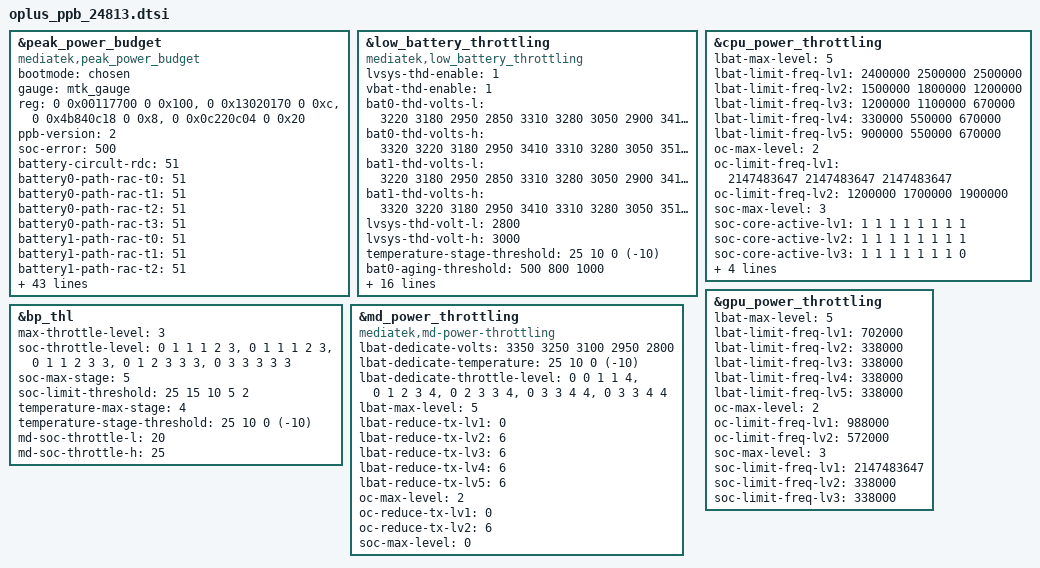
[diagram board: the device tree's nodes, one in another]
// SPDX-License-Identifier: GPL-2.0-only
/*
* Copyright (C) 2021-2020 Oplus. All rights reserved.
*/
#include <dt-bindings/iio/mt635x-auxadc.h>
#include <dt-bindings/pinctrl/mt6991-pinfunc.h>
#include <dt-bindings/pinctrl/mt65xx.h>

&peak_power_budget {
	compatible = "mediatek,peak_power_budget";
	bootmode = <&chosen>;
	gauge = <&mtk_gauge>;
	reg = <0 0x00117700 0 0x100>,
		<0 0x13020170 0 0xc>,
		<0 0x4b840c18 0 0x8>,
		<0 0x0c220c04 0 0x20>;
	reg-names = "ppb_sram",
		"hpt_ctrl","gpu_dbg", "cpu_dbg";

	ppb-version = <2>;
	soc-error = <500>;
	battery-circult-rdc  = <51>;
	battery0-path-rac-t0 = <51>;
	battery0-path-rac-t1 = <51>;
	battery0-path-rac-t2 = <51>;
	battery0-path-rac-t3 = <51>;
	battery1-path-rac-t0 = <51>;
	battery1-path-rac-t1 = <51>;
	battery1-path-rac-t2 = <51>;
	battery1-path-rac-t3 = <51>;
	battery2-path-rac-t0 = <51>;
	battery2-path-rac-t1 = <51>;
	battery2-path-rac-t2 = <51>;
	battery2-path-rac-t3 = <51>;
	temperature-threshold = <25 10 0>;
	system-ocp = <15000>;
	system-uvlo = <2400>;

	soc-max-level = <3>;     //+lv3
	soc-hpt-ctrl-lv1 = <7>;  //lv1 pre-uv on
	soc-hpt-ctrl-lv2 = <0>;  //lv2 pre-uv off
	soc-hpt-ctrl-lv3 = <0>;  //lv3 pre-uv off

	bat-ocv-table-num = <6>;
	bat0-ocv-table-t0-temperature = <50>;
		bat0-ocv-table-t0-qmax = <6498>;
	bat0-ocv-table-t0-size = <100>;
	bat0-ocv-table-t0 = <
		0	44457 	0 	271
656	44330 	101 	271
1313	44219 	202 	268
1969	44119 	303 	270
2625	44024 	404 	272
3282	43926 	505 	267
3938	43829 	606 	270
4594	43730 	707 	268
5251	43630 	808 	269
5907	43527 	909 	272
6563	43422 	1010 	273
7220	43313 	1111 	267
7876	43209 	1212 	280
8532	43097 	1313 	285
9189	42982 	1414 	286
9845	42864 	1515 	286
10501	42745 	1616 	285
11157	42625 	1717 	283
11814	42506 	1818 	288
12470	42385 	1919 	292
13126	42264 	2020 	296
13783	42142 	2121 	303
14439	42023 	2222 	309
15095	41901 	2323 	319
15752	41782 	2424 	328
16408	41661 	2525 	339
17064	41537 	2626 	352
17721	41409 	2727 	364
18377	41267 	2828 	378
19033	41073 	2929 	340
19690	40883 	3030 	304
20346	40719 	3131 	284
21002	40587 	3232 	278
21659	40470 	3333 	274
22315	40358 	3434 	272
22971	40253 	3535 	271
23628	40149 	3636 	271
24284	40047 	3737 	272
24940	39951 	3838 	276
25597	39855 	3939 	282
26253	39763 	4040 	282
26909	39671 	4141 	287
27566	39582 	4242 	291
28222	39496 	4343 	296
28878	39410 	4444 	306
29534	39326 	4545 	315
30191	39236 	4646 	324
30847	39121 	4747 	313
31503	38982 	4848 	290
32160	38836 	4950 	279
32816	38725 	5050 	286
33472	38611 	5151 	286
34129	38500 	5253 	286
34785	38394 	5354 	286
35441	38293 	5454 	288
36098	38191 	5556 	298
36754	38072 	5657 	305
37410	37953 	5758 	313
38067	37837 	5859 	320
38723	37722 	5960 	328
39379	37607 	6061 	335
40036	37511 	6162 	316
40692	37441 	6263 	311
41348	37377 	6364 	313
42005	37310 	6465 	327
42661	37231 	6566 	364
43317	37122 	6667 	452
43974	37010 	6768 	300
44630	36897 	6869 	275
45286	36777 	6970 	250
45943	36651 	7071 	225
46599	36521 	7172 	200
47255	36387 	7273 	175
47912	36241 	7374 	150
48568	36089 	7475 	125
49224	35931 	7576 	100
49880	35769 	7677 	100
50537	35609 	7778 	100
51193	35452 	7879 	100
51849	35300 	7980 	100
52506	35151 	8081 	100
53162	34999 	8182 	100
53818	34844 	8283 	100
54475	34687 	8384 	100
55131	34516 	8485 	100
55787	34337 	8586 	100
56444	34146 	8687 	100
57100	33943 	8788 	100
57756	33727 	8889 	350
58413	33491 	8990 	600
59069	33249 	9091 	600
59725	33009 	9192 	600
60382	32772 	9293 	548
61038	32537 	9394 	495
61694	32294 	9495 	443
62351	32021 	9596 	390
63007	31687 	9697 	390
63663	31238 	9798 	390
64320	30613 	9899 	295
64976	29753 	10000 	200
					>;

					bat0-ocv-table-t1-temperature = <25>;
					bat0-ocv-table-t1-qmax = <6559>;
					bat0-ocv-table-t1-size = <100>;
					bat0-ocv-table-t1 = <
			0	44581 	0 	543
663	44445 	101 	543
1325	44333 	202 	527
1988	44235 	303 	525
2650	44142 	404 	527
3313	44048 	505 	520
3975	43955 	606 	520
4638	43858 	707 	514
5300	43760 	808 	514
5963	43661 	909 	514
6625	43559 	1010 	511
7288	43454 	1111 	512
7950	43348 	1212 	519
8613	43236 	1313 	522
9275	43123 	1414 	521
9938	43007 	1515 	522
10601	42889 	1616 	528
11263	42768 	1717 	532
11926	42647 	1818 	541
12588	42524 	1919 	543
13251	42401 	2020 	552
13913	42279 	2121 	566
14576	42158 	2222 	581
15238	42034 	2323 	594
15901	41908 	2424 	607
16563	41787 	2525 	625
17226	41663 	2626 	642
17888	41536 	2727 	660
18551	41403 	2828 	673
19214	41256 	2929 	670
19876	41071 	3030 	625
20539	40869 	3131 	559
21201	40694 	3232 	515
21864	40548 	3333 	495
22526	40420 	3434 	485
23189	40307 	3535 	485
23851	40199 	3636 	485
24514	40095 	3737 	487
25176	39994 	3838 	485
25839	39895 	3939 	481
26501	39798 	4040 	482
27164	39709 	4141 	488
27826	39616 	4242 	488
28489	39530 	4343 	496
29152	39446 	4445 	506
29814	39363 	4545 	512
30477	39279 	4647 	513
31139	39197 	4747 	523
31802	39112 	4849 	526
32464	39016 	4949 	516
33127	38910 	5051 	498
33789	38796 	5151 	482
34452	38681 	5253 	473
35114	38568 	5353 	473
35777	38462 	5455 	470
36439	38358 	5555 	471
37102	38249 	5657 	476
37764	38131 	5757 	482
38427	38006 	5859 	489
39090	37896 	5960 	495
39752	37774 	6061 	504
40415	37653 	6162 	502
41077	37552 	6263 	496
41740	37480 	6364 	497
42402	37419 	6465 	500
43065	37357 	6566 	520
43727	37275 	6667 	557
44390	37157 	6768 	668
45052	37026 	6869 	300
45715	36907 	6970 	275
46377	36781 	7071 	250
47040	36655 	7172 	225
47702	36527 	7273 	200
48365	36392 	7374 	175
49028	36247 	7475 	150
49690	36094 	7576 	125
50353	35938 	7677 	100
51015	35776 	7778 	100
51678	35615 	7879 	100
52340	35453 	7980 	100
53003	35293 	8081 	100
53665	35139 	8182 	100
54328	34985 	8283 	100
54990	34829 	8384 	100
55653	34667 	8485 	100
56315	34490 	8586 	100
56978	34297 	8687 	100
57641	34095 	8788 	100
58303	33872 	8889 	350
58966	33631 	8990 	600
59628	33381 	9091 	600
60291	33132 	9192 	600
60953	32889 	9293 	558
61616	32658 	9394 	516
62278	32422 	9495 	474
62941	32171 	9596 	432
63603	31870 	9697 	390
64266	31471 	9798 	600
64928	30914 	9899 	390
65591	30134 	10000 	200
						>;

					bat0-ocv-table-t2-temperature = <10>;
					bat0-ocv-table-t2-qmax = <6489>;
					bat0-ocv-table-t2-size = <100>;
					bat0-ocv-table-t2 = <
			0	44556 	0 	997
655	44417 	101 	997
1311	44305 	202 	992
1966	44207 	303 	986
2622	44116 	404 	977
3277	44029 	505 	961
3932	43935 	606 	948
4588	43844 	707 	945
5243	43750 	808 	942
5899	43654 	909 	941
6554	43556 	1010 	942
7209	43452 	1111 	935
7865	43346 	1212 	926
8520	43236 	1313 	919
9176	43123 	1414 	920
9831	43008 	1515 	926
10487	42892 	1616 	932
11142	42773 	1717 	935
11797	42652 	1818 	930
12453	42530 	1919 	932
13108	42407 	2020 	941
13764	42283 	2121 	952
14419	42159 	2222 	958
15074	42038 	2323 	968
15730	41914 	2424 	979
16385	41789 	2525 	989
17041	41662 	2626 	997
17696	41532 	2727 	1009
18351	41393 	2828 	1002
19007	41234 	2929 	975
19662	41057 	3030 	930
20318	40873 	3131 	875
20973	40700 	3232 	822
21628	40548 	3333 	787
22284	40420 	3434 	779
22939	40302 	3535 	775
23595	40191 	3636 	774
24250	40084 	3737 	775
24906	39982 	3838 	769
25561	39881 	3939 	762
26216	39784 	4040 	769
26872	39691 	4141 	773
27527	39599 	4242 	780
28183	39509 	4344 	797
28838	39423 	4444 	803
29493	39339 	4545 	807
30149	39256 	4647 	814
30804	39173 	4747 	821
31460	39092 	4849 	826
32115	39011 	4950 	835
32770	38922 	5050 	832
33426	38825 	5152 	818
34081	38722 	5253 	803
34737	38612 	5354 	787
35392	38496 	5455 	773
36047	38389 	5556 	769
36703	38280 	5657 	775
37358	38162 	5758 	775
38014	38039 	5859 	500
38669	37917 	5960 	480
39324	37800 	6061 	460
39980	37670 	6162 	440
40635	37557 	6263 	420
41291	37471 	6364 	400
41946	37403 	6465 	380
42602	37341 	6566 	360
43257	37276 	6667 	340
43912	37170 	6768 	320
44568	37024 	6869 	300
45223	36878 	6970 	271
45879	36747 	7071 	243
46534	36620 	7172 	214
47189	36491 	7273 	186
47845	36355 	7374 	157
48500	36215 	7475 	129
49156	36069 	7576 	100
49811	35916 	7677 	100
50466	35758 	7778 	100
51122	35594 	7879 	100
51777	35431 	7980 	100
52433	35270 	8081 	100
53088	35111 	8182 	100
53743	34954 	8283 	100
54399	34799 	8384 	100
55054	34636 	8485 	100
55710	34463 	8586 	100
56365	34281 	8687 	100
57021	34088 	8788 	100
57676	33877 	8889 	350
58331	33646 	8990 	600
58987	33404 	9091 	600
59642	33155 	9192 	600
60298	32904 	9293 	600
60953	32660 	9394 	548
61608	32422 	9495 	495
62264	32171 	9596 	443
62919	31886 	9697 	390
63575	31531 	9798 	390
64230	31059 	9899 	390
64885	30388 	10000 	200
						>;
					bat0-ocv-table-t3-temperature = <0>;
					bat0-ocv-table-t3-qmax = <6223>;
					bat0-ocv-table-t3-size = <100>;
					bat0-ocv-table-t3 = <
			0	44556 	0 	1922
629	44405 	101 	1922
1257	44285 	202 	1910
1886	44189 	303 	1677
2514	44105 	404 	1368
3143	44012 	505 	1837
3771	43922 	606 	1867
4400	43833 	707 	1864
5028	43742 	808 	1856
5657	43647 	909 	1838
6285	43557 	1010 	1820
6914	43459 	1111 	1807
7543	43359 	1212 	1798
8171	43258 	1313 	1792
8800	43155 	1414 	1786
9428	43047 	1515 	1782
10057	42936 	1616 	1772
10685	42823 	1717 	1763
11314	42708 	1818 	1759
11942	42593 	1919 	1758
12571	42474 	2020 	1753
13200	42355 	2121 	1749
13828	42235 	2222 	1745
14457	42115 	2323 	1739
15085	41996 	2424 	1739
15714	41874 	2525 	1739
16342	41746 	2626 	1728
16971	41614 	2727 	1712
17599	41481 	2828 	1698
18228	41337 	2929 	1664
18856	41178 	3030 	1616
19485	41013 	3131 	1566
20114	40850 	3232 	1521
20742	40694 	3333 	1484
21371	40559 	3434 	1462
21999	40433 	3535 	1445
22628	40315 	3636 	1434
23256	40204 	3737 	1428
23885	40100 	3838 	1425
24513	39999 	3939 	1428
25142	39901 	4040 	1427
25771	39805 	4142 	1408
26399	39712 	4242 	1366
27028	39625 	4344 	1413
27656	39534 	4444 	1435
28285	39448 	4546 	1443
28913	39365 	4646 	1445
29542	39282 	4748 	1444
30170	39204 	4848 	1432
30799	39126 	4950 	1422
31427	39048 	5050 	1438
32056	38969 	5152 	1453
32685	38889 	5253 	1337
33313	38801 	5354 	1439
33942	38710 	5455 	1408
34570	38615 	5556 	1310
35199	38516 	5657 	1252
35827	38411 	5758 	1362
36456	38306 	5859 	1415
37084	38194 	5960 	1415
37713	38075 	6061 	1382
38342	37953 	6162 	1347
38970	37838 	6263 	1357
39599	37718 	6364 	1292
40227	37601 	6465 	1298
40856	37497 	6566 	1378
41484	37421 	6667 	1424
42113	37359 	6768 	1446
42741	37297 	6869 	1445
43370	37218 	6970 	1465
43998	37107 	7071 	1517
44627	36935 	7172 	1280
45256	36766 	7273 	1280
45884	36617 	7374 	1280
46513	36486 	7475 	1280
47141	36363 	7576 	1280
47770	36233 	7677 	1280
48398	36102 	7778 	1280
49027	35967 	7879 	1280
49655	35820 	7980 	1242
50284	35649 	8081 	1203
50913	35492 	8182 	1165
51541	35341 	8283 	1127
52170	35187 	8384 	1088
52798	35032 	8485 	1050
53427	34885 	8586 	1008
54055	34724 	8687 	967
54684	34549 	8788 	925
55312	34373 	8889 	883
55941	34203 	8990 	842
56569	34036 	9091 	800
57198	33844 	9192 	760
57827	33646 	9293 	720
58455	33432 	9394 	680
59084	33189 	9495 	640
59712	32933 	9596 	600
60341	32692 	9697 	600
60969	32462 	9798 	600
61598	32230 	9899 	600
62226	31979 	10000 	600
					>;

					bat0-ocv-table-t4-temperature = <(-10)>;
					bat0-ocv-table-t4-qmax = <5761>;
					bat0-ocv-table-t4-size = <100>;
					bat0-ocv-table-t4 = <
						0	44804 	0 	3799
			582	44581 	101 	3799
			1164	44415 	202 	3797
			1746	44292 	303 	3794
			2328	44190 	404 	3791
			2910	44095 	505 	3784
			3492	44005 	606 	3774
			4073	43919 	707 	3743
			4655	43833 	808 	3589
			5237	43746 	909 	3644
			5819	43657 	1010 	3719
			6401	43567 	1111 	3713
			6983	43477 	1212 	3699
			7565	43385 	1313 	3689
			8147	43292 	1414 	3682
			8729	43197 	1515 	3675
			9311	43099 	1616 	3665
			9893	42998 	1717 	3656
			10475	42897 	1818 	3650
			11057	42795 	1919 	3639
			11639	42691 	2020 	3634
			12220	42584 	2121 	3627
			12802	42475 	2222 	3613
			13384	42365 	2323 	3601
			13966	42251 	2424 	3584
			14548	42136 	2525 	3567
			15130	42019 	2626 	3556
			15712	41895 	2727 	3530
			16294	41770 	2828 	3504
			16876	41643 	2929 	3480
			17458	41510 	3030 	3446
			18040	41375 	3131 	3417
			18622	41238 	3232 	3383
			19204	41098 	3333 	3341
			19786	40963 	3434 	3307
			20367	40832 	3535 	3279
			20949	40705 	3636 	3251
			21531	40583 	3737 	3217
			22113	40468 	3838 	3204
			22695	40356 	3939 	3194
			23277	40248 	4040 	3185
			23859	40147 	4141 	3167
			24441	40047 	4242 	3156
			25023	39951 	4343 	3149
			25605	39858 	4444 	3144
			26187	39768 	4545 	3141
			26769	39679 	4647 	3141
			27351	39592 	4748 	3143
			27933	39509 	4849 	3144
			28514	39426 	4949 	3143
			29096	39344 	5050 	3142
			29678	39266 	5151 	3139
			30260	39190 	5252 	3137
			30842	39111 	5353 	3143
			31424	39034 	5455 	3148
			32006	38959 	5556 	3150
			32588	38880 	5657 	3151
			33170	38803 	5758 	3158
			33752	38726 	5859 	3167
			34334	38647 	5960 	3174
			34916	38562 	6061 	3164
			35498	38474 	6162 	3163
			36080	38383 	6263 	3170
			36661	38291 	6364 	3164
			37243	38192 	6465 	3163
			37825	38089 	6566 	3164
			38407	37983 	6667 	3166
			38989	37873 	6768 	3163
			39571	37759 	6869 	3171
			40153	37646 	6970 	3184
			40735	37538 	7071 	3189
			41317	37457 	7172 	3210
			41899	37388 	7273 	3234
			42481	37325 	7374 	3262
			43063	37261 	7475 	3304
			43645	37185 	7576 	3367
			44226	37068 	7677 	3440
			44808	36891 	7778 	3516
			45390	36671 	7879 	3664
			45972	36491 	7980 	3804
			46554	36342 	8081 	3932
			47136	36214 	8182 	4038
			47718	36087 	8283 	4140
			48300	35959 	8384 	4245
			48882	35827 	8485 	4356
			49464	35692 	8586 	4480
			50046	35549 	8687 	4621
			50628	35399 	8788 	4776
			51210	35244 	8889 	4946
			51792	35083 	8990 	5140
			52373	34920 	9091 	5365
			52955	34757 	9192 	5616
			53537	34597 	9293 	5889
			54119	34437 	9394 	6200
			54701	34278 	9495 	6559
			55283	34120 	9596 	6957
			55865	33964 	9697 	7326
			56447	33811 	9798 	7699
			57029	33652 	9899 	8073
			57611	33485 	10000 	8442
					>;

					bat0-ocv-table-t5-temperature = <(-20)>;
					bat0-ocv-table-t5-qmax = <5120>;
					bat0-ocv-table-t5-size = <100>;
					bat0-ocv-table-t5 = <
						0	44739 	0 	7520
			517	44504 	101 	7520
			1034	44305 	202 	7527
			1552	44149 	303 	7542
			2069	44014 	404 	7530
			2586	43887 	505 	7511
			3103	43769 	606 	7485
			3620	43654 	707 	7452
			4138	43541 	808 	7418
			4655	43431 	909 	7382
			5172	43323 	1010 	7351
			5689	43217 	1111 	7323
			6206	43111 	1212 	7303
			6724	43007 	1313 	7283
			7241	42905 	1414 	7262
			7758	42802 	1515 	7234
			8275	42700 	1616 	7207
			8792	42598 	1717 	7179
			9310	42498 	1818 	7159
			9827	42397 	1919 	7140
			10344	42295 	2020 	7122
			10861	42194 	2121 	7089
			11378	42093 	2222 	7055
			11896	41991 	2323 	7022
			12413	41887 	2424 	7000
			12930	41783 	2525 	6978
			13447	41679 	2626 	6951
			13964	41575 	2727 	6919
			14482	41470 	2828 	6889
			14999	41364 	2929 	6869
			15516	41259 	3030 	6846
			16033	41154 	3131 	6821
			16550	41048 	3232 	6798
			17068	40943 	3333 	6766
			17585	40839 	3434 	6724
			18102	40735 	3535 	6705
			18619	40632 	3636 	6683
			19136	40532 	3737 	6655
			19654	40432 	3838 	6624
			20171	40333 	3939 	6601
			20688	40236 	4040 	6595
			21205	40143 	4141 	6584
			21722	40051 	4242 	6571
			22240	39959 	4343 	6556
			22757	39871 	4444 	6546
			23274	39785 	4545 	6539
			23791	39703 	4646 	6534
			24308	39621 	4747 	6530
			24826	39539 	4849 	6528
			25343	39463 	4950 	6528
			25860	39387 	5050 	6532
			26377	39311 	5151 	6541
			26894	39240 	5252 	6538
			27412	39169 	5354 	6536
			27929	39097 	5455 	6536
			28446	39028 	5556 	6540
			28963	38960 	5657 	6540
			29480	38890 	5757 	6531
			29998	38824 	5859 	6544
			30515	38760 	5960 	6558
			31032	38693 	6061 	6557
			31549	38629 	6162 	6571
			32066	38565 	6263 	6591
			32584	38500 	6364 	6596
			33101	38436 	6465 	6608
			33618	38372 	6566 	6624
			34135	38308 	6667 	6631
			34652	38242 	6768 	6642
			35170	38174 	6869 	6658
			35687	38108 	6970 	6673
			36204	38041 	7071 	6691
			36721	37975 	7172 	6712
			37238	37906 	7273 	6733
			37756	37837 	7374 	6753
			38273	37771 	7475 	6772
			38790	37702 	7576 	6794
			39307	37633 	7677 	6821
			39824	37569 	7778 	6863
			40342	37507 	7879 	6906
			40859	37447 	7980 	6951
			41376	37389 	8081 	6999
			41893	37330 	8182 	7057
			42410	37270 	8283 	7122
			42928	37203 	8384 	7205
			43445	37126 	8485 	7293
			43962	37036 	8586 	7388
			44479	36909 	8687 	7481
			44996	36759 	8788 	7578
			45514	36576 	8889 	7681
			46031	36369 	8990 	7806
			46548	36159 	9091 	7943
			47065	35954 	9192 	8096
			47582	35765 	9293 	8269
			48099	35584 	9394 	8451
			48617	35417 	9495 	8643
			49134	35254 	9596 	8850
			49651	35092 	9697 	9066
			50168	34933 	9798 	9304
			50685	34772 	9899 	9552
			51203	34608 	10000 	9807
						>;
	};

&low_battery_throttling {
		compatible = "mediatek,low_battery_throttling";
		lvsys-thd-enable = <1>;
		vbat-thd-enable = <1>;
		bat0-thd-volts-l = <
			3220 3180 2950 2850    //PT threshhold down
			3310 3280 3050 2900
			3410 3340 3150 3000
			3580 3500 3350 3200
			3720 3620 3560 3350>;
		bat0-thd-volts-h = <
			3320 3220 3180 2950
			3410 3310 3280 3050
			3510 3410 3340 3150
			3680 3580 3500 3350
			3820 3720 3620 3560>;
		bat1-thd-volts-l = <
			3220 3180 2950 2850    //PT threshhold down
			3310 3280 3050 2900
			3410 3340 3150 3000
			3580 3500 3350 3200
			3720 3620 3560 3350>;
		bat1-thd-volts-h = <
			3320 3220 3180 2950
			3410 3310 3280 3050
			3510 3410 3340 3150
			3680 3580 3500 3350
			3820 3720 3620 3560>;
		lvsys-thd-volt-l = <2800>;   //0.1V down
		lvsys-thd-volt-h = <3000>;   //0.1V down

		temperature-stage-threshold = <25 10 0 (-10)>;
		bat0-aging-threshold = <500 800 1000>;
		bat0-aging-volts-t0 =  <50 100 150>;
		bat0-aging-volts-t1 =  <50 100 150>;
		bat0-aging-volts-t2 =  <50 100 150>;
		bat0-aging-volts-t3 =  <50 100 150>;
		bat0-aging-volts-t4 =  <50 100 150>;
		bat1-aging-threshold = <500 800 1000>;
		bat1-aging-volts-t0 =  <0 0>;
		bat1-aging-volts-t1 =  <0 0>;
		bat1-aging-volts-t2 =  <0 0>;
		bat1-aging-volts-t3 =  <0 0>;
		bat1-aging-volts-t4 =  <0 0>;
		pt-shutdown-enable = <0>;
		throttle-level =  <0 1 2 3 4>,
				  <0 1 2 3 4>,
				  <0 1 2 3 4>,
				  <0 1 3 5 4>,
				  <0 1 3 5 4>;
		bootmode = <&chosen>;
		gauge = <&mtk_gauge>;
};

	&cpu_power_throttling {
		lbat-max-level = <5>;
		lbat-limit-freq-lv1 = < 2400000  2500000 2500000>;
		lbat-limit-freq-lv2 = < 1500000  1800000 1200000>;
		lbat-limit-freq-lv3 = < 1200000  1100000 670000>;
		lbat-limit-freq-lv4 = < 330000   550000 670000>;
		lbat-limit-freq-lv5 = < 900000   550000 670000>;

		oc-max-level = <2>;
		oc-limit-freq-lv1 = < 2147483647  2147483647 2147483647>;
		oc-limit-freq-lv2 = < 1200000  1700000 1900000>;

		soc-max-level = <3>;
		soc-core-active-lv1 = < 1 1 1 1 1 1 1 1 >;
		soc-core-active-lv2 = < 1 1 1 1 1 1 1 1 >;
		soc-core-active-lv3 = < 1 1 1 1 1 1 1 0 >;

		soc-limit-freq-lv1 = < 2147483647  2147483647 2147483647 >;
		soc-limit-freq-lv2 = < 2100000 2100000 1100000>;
		soc-limit-freq-lv3 = < 1800000 1800000 1100000>;
	};

	&gpu_power_throttling {
		lbat-max-level = <5>;
		lbat-limit-freq-lv1 = <702000>;
		lbat-limit-freq-lv2 = <338000>;
		lbat-limit-freq-lv3 = <338000>;
		lbat-limit-freq-lv4 = <338000>;
		lbat-limit-freq-lv5 = <338000>;

		oc-max-level = <2>;
		oc-limit-freq-lv1 = <988000>;
		oc-limit-freq-lv2 = <572000>;

		soc-max-level = <3>;
		soc-limit-freq-lv1 = <2147483647>;
		soc-limit-freq-lv2 = <338000>;
		soc-limit-freq-lv3 = <338000>;
	};

	&bp_thl {
		max-throttle-level = <3>;   //+lv3
		soc-throttle-level =
			<0 1 1 1 2 3>, //temperature stage 0
			<0 1 1 1 2 3>, //temperature stage 1
			<0 1 1 2 3 3>, //temperature stage 2
			<0 1 2 3 3 3>,//temperature stage 3
                        <0 3 3 3 3 3>;//temperature stage 4
		soc-max-stage = <5>;
		soc-limit-threshold = <25 15 10 5 2>;

		temperature-max-stage = <4>;
		temperature-stage-threshold = <25 10 0 (-10)>;

		md-soc-throttle-l = <20>;
		md-soc-throttle-h = <25>;
	};

	&md_power_throttling {
		compatible = "mediatek,md-power-throttling";

		lbat-dedicate-volts = <3350 3250 3100 2950 2800>;
		lbat-dedicate-temperature = <25 10 0 (-10)>;
		lbat-dedicate-throttle-level =  < 0 0 1 1 4>,
						< 0 1 2 3 4>,
						< 0 2 3 3 4>,
						< 0 3 3 4 4>,
						< 0 3 3 4 4>;

		lbat-max-level = <5>;
		lbat-reduce-tx-lv1 = <0>;
		lbat-reduce-tx-lv2 = <6>;
		lbat-reduce-tx-lv3 = <6>;
		lbat-reduce-tx-lv4 = <6>;
		lbat-reduce-tx-lv5 = <6>;

		oc-max-level = <2>;
		oc-reduce-tx-lv1 = <0>;
		oc-reduce-tx-lv2 = <6>;

		soc-max-level = <0>;
	};
